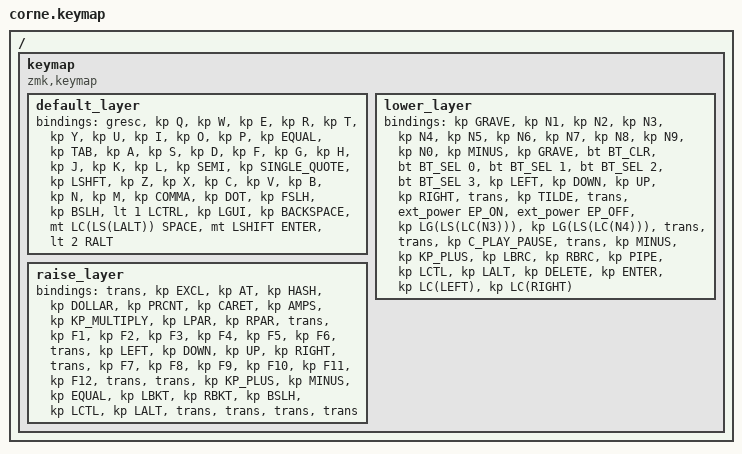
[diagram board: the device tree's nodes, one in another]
/*
 * Copyright (c) 2020 The ZMK Contributors
 *
 * SPDX-License-Identifier: MIT
 */

#include <behaviors.dtsi>
#include <dt-bindings/zmk/keys.h>
#include <dt-bindings/zmk/bt.h>
#include <dt-bindings/zmk/ext_power.h>
#include <dt-bindings/zmk/outputs.h>

/ {
        keymap {
                compatible = "zmk,keymap";

                default_layer {
// -----------------------------------------------------------------------------------------
// |  TAB |  Q  |  W  |  E  |  R  |  T  |   |  Y  |  U   |  I  |  O  |  P  | BKSP |
// | CTRL |  A  |  S  |  D  |  F  |  G  |   |  H  |  J   |  K  |  L  |  ;  |  '   |
// | SHFT |  Z  |  X  |  C  |  V  |  B  |   |  N  |  M   |  ,  |  .  |  /  | ESC  |
//                    | GUI | LWR | SPC |   | ENT | RSE  | ALT |
                        bindings = <
&gresc   &kp Q  &kp W  &kp E    &kp R    &kp T                      &kp Y  &kp U    &kp I     &kp O   &kp P    &kp EQUAL
&kp TAB   &kp A  &kp S  &kp D    &kp F    &kp G                      &kp H  &kp J    &kp K     &kp L   &kp SEMI &kp SINGLE_QUOTE
&kp LSHFT &kp Z  &kp X  &kp C    &kp V    &kp B                     &kp N  &kp M    &kp COMMA &kp DOT &kp FSLH &kp BSLH
                &lt 1 LCTRL &kp LGUI  &kp BACKSPACE             &mt LC(LS(LALT)) SPACE &mt LSHIFT ENTER &lt 2 RALT
                        >;
                };
                lower_layer {
// -----------------------------------------------------------------------------------------
// |  TAB |  1  |  2  |  3  |  4  |  5  |   |  6  |  7  |  8  |  9  |  0  | BKSP |
// | BTCLR| BT1 | BT2 | BT3 | BT4 | BT5 |   | LFT | DWN |  UP | RGT |     |      |
// | SHFT |     |     |     |     |     |   |     |     |     |     |     |      |
//                    | GUI |     | SPC |   | ENT |     | ALT |
                        bindings = <
&kp GRAVE &kp N1 &kp N2 &kp N3 &kp N4   &kp N5                 &kp N6      &kp N7    &kp N8    &kp N9   &kp N0   &kp MINUS
&kp GRAVE &bt BT_CLR &bt BT_SEL 0 &bt BT_SEL 1 &bt BT_SEL 2 &bt BT_SEL 3                &kp LEFT     &kp DOWN  &kp UP    &kp RIGHT  &trans   &kp TILDE
&trans     &ext_power EP_ON &ext_power EP_OFF &kp LG(LS(LC(N3))) &kp LG(LS(LC(N4)))   &trans    &trans   &kp C_PLAY_PAUSE   &trans    &kp MINUS &kp KP_PLUS     &kp LBRC  &kp RBRC  &kp PIPE
                                        &kp LCTL  &kp LALT &kp DELETE            &kp ENTER  &kp LC(LEFT)  &kp LC(RIGHT)
                        >;
                };

                raise_layer {
// -----------------------------------------------------------------------------------------
// |  TAB |  !  |  @  |  #  |  $  |  %  |   |  ^  |  &  |  *  |  (  |  )  | BKSP |
// | CTRL |     |     |     |     |     |   |  -  |  =  |  [  |  ]  |  \  |  `   |
// | SHFT |     |     |     |     |     |   |  _  |  +  |  {  |  }  | "|" |  ~   |
//                    | GUI |     | SPC |   | ENT |     | ALT |
                        bindings = <
&trans &kp EXCL &kp AT &kp HASH &kp DOLLAR &kp PRCNT                 &kp CARET &kp AMPS  &kp KP_MULTIPLY &kp LPAR  &kp RPAR &trans
&kp F1    &kp F2 &kp F3 &kp F4  &kp F5  &kp F6                       &trans      &kp LEFT  &kp DOWN  &kp UP   &kp RIGHT &trans
&kp F7    &kp F8 &kp F9 &kp F10 &kp F11 &kp F12   &trans   &trans    &kp KP_PLUS &kp MINUS &kp EQUAL &kp LBKT &kp RBKT  &kp BSLH
                   	     &kp LCTL  &kp LALT    &trans   &trans    &trans      &trans
                        >;
                };
        };
};
